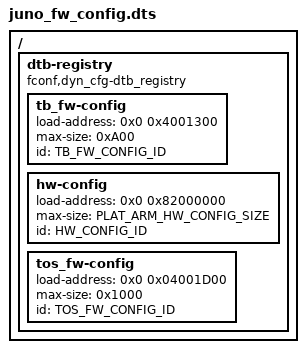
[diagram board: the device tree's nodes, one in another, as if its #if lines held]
/*
 * Copyright (c) 2019-2025, Arm Limited. All rights reserved.
 *
 * SPDX-License-Identifier: BSD-3-Clause
 */

#include <common/tbbr/tbbr_img_def.h>
#include <platform_def.h>

/dts-v1/;

/ {
	dtb-registry {
		compatible = "fconf,dyn_cfg-dtb_registry";

		tb_fw-config {
			load-address = <0x0 0x4001300>;
			max-size = <0xA00>;
			id = <TB_FW_CONFIG_ID>;
		};


		hw-config {
			load-address = <0x0 0x82000000>;
			max-size = <PLAT_ARM_HW_CONFIG_SIZE>;
			id = <HW_CONFIG_ID>;
		};

#if SPMC_AT_EL3
		tos_fw-config {
			load-address = <0x0 0x04001D00>;
			max-size = <0x1000>;
			id = <TOS_FW_CONFIG_ID>;
		};
#endif
	};
};
